# ATmega324PB device description
Architecture: AVR8; Family: megaAVR
Registers are 8-bit, access not given, no defined reset value unless marked. A register's access mark holds for its fields unless they carry their own. Offsets are from the block's base; [hi:lo] are bit positions.

## LOCKBIT — Lockbits
Instances: LOCKBIT 0 in lockbits
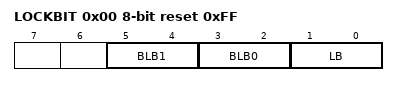
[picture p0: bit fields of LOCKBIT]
0x00 LOCKBIT reset 0xFF
  [5:4] BLB1 — Boot Loader Protection Mode
    0=LPM_SPM_DISABLE (LPM and SPM prohibited in Boot Section); 1=LPM_DISABLE (LPM prohibited in Boot Section); 2=SPM_DISABLE (SPM prohibited in Boot Section); 3=NO_LOCK (No lock on SPM and LPM in Boot Section)
  [3:2] BLB0 — Boot Loader Protection Mode
    0=LPM_SPM_DISABLE (LPM and SPM prohibited in Application Section); 1=LPM_DISABLE (LPM prohibited in Application Section); 2=SPM_DISABLE (SPM prohibited in Application Section); 3=NO_LOCK (No lock on SPM and LPM in Application Section)
  [1:0] LB — Memory Lock
    0=PROG_VER_DISABLED (Further programming and verification disabled); 2=PROG_DISABLED (Further programming disabled); 3=NO_LOCK (No memory lock features enabled)

## AC — Analog Comparator
Instances: AC 0x00
0x4F ACSRB — Analog Comparator Control And Status Register B
  [0] ACOE — Analog Comparator Output enable
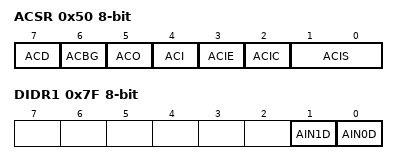
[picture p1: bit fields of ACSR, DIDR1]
0x50 ACSR — Analog Comparator Control And Status Register
  [7] ACD — Analog Comparator Disable
  [6] ACBG — Analog Comparator Bandgap Select
  [5] ACO — Analog Compare Output
  [4] ACI — Analog Comparator Interrupt Flag
  [3] ACIE — Analog Comparator Interrupt Enable
  [2] ACIC — Analog Comparator Input Capture Enable
  [1:0] ACIS — Analog Comparator Interrupt Mode Select bits
    0=Interrupt on Toggle; 2=Interrupt on Falling Edge; 3=Interrupt on Rising Edge
0x7F DIDR1 — Digital Input Disable Register 1
  [1] AIN1D — AIN1 Digital Input Disable
  [0] AIN0D — AIN0 Digital Input Disable

## USART0 — USART
Instances: USART0 0x00
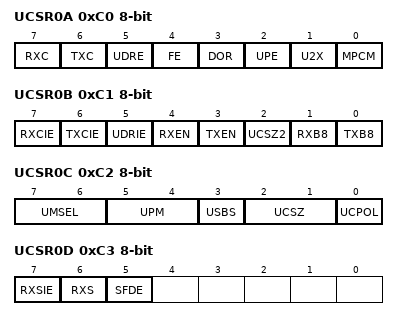
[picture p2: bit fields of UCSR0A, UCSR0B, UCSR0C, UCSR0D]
0xC0 UCSR0A — USART Control and Status Register A
  [7] RXC — USART Receive Complete
  [6] TXC — USART Transmitt Complete
  [5] UDRE — USART Data Register Empty
  [4] FE — Framing Error
  [3] DOR — Data overRun
  [2] UPE — Parity Error
  [1] U2X — Double the USART transmission speed
  [0] MPCM — Multi-processor Communication Mode
0xC1 UCSR0B — USART Control and Status Register B
  [7] RXCIE — RX Complete Interrupt Enable
  [6] TXCIE — TX Complete Interrupt Enable
  [5] UDRIE — USART Data register Empty Interrupt Enable
  [4] RXEN — Receiver Enable
  [3] TXEN — Transmitter Enable
  [2] UCSZ2 — Character Size
  [1] RXB8 — Receive Data Bit 8
  [0] TXB8 — Transmit Data Bit 8
0xC2 UCSR0C — USART Control and Status Register C
  [7:6] UMSEL — USART Mode Select
    0=Asynchronous Operation; 1=Synchronous Operation; 3=Master SPI
  [5:4] UPM — Parity Mode Bits
    0=Disabled; 2=Enabled, Even Parity; 3=Enabled, Odd Parity
  [3] USBS — Stop Bit Select
    0=1-bit; 1=2-bit
  [2:1] UCSZ — Character Size
  [0] UCPOL — Clock Polarity
0xC3 UCSR0D — USART Control and Status Register D
  [7] RXSIE — RX Start Frame Interrupt Enable
  [6] RXS — Start Frame Detect Flag
  [5] SFDE — Start Frame Detection Enable
0xC4 UBRR0 16-bit bits used 11:0 — USART Baud Rate Register Bytes
0xC6 UDR0 — USART I/O Data Register

## USART1 — USART
Instances: USART1 0x00
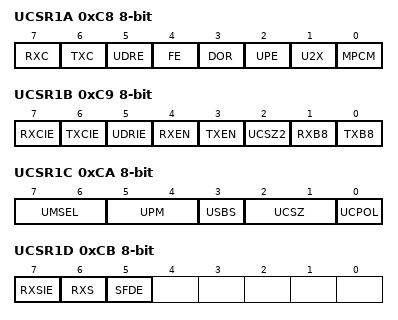
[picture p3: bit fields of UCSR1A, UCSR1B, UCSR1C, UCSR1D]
0xC8 UCSR1A — USART Control and Status Register A
  [7] RXC — USART Receive Complete
  [6] TXC — USART Transmitt Complete
  [5] UDRE — USART Data Register Empty
  [4] FE — Framing Error
  [3] DOR — Data overRun
  [2] UPE — Parity Error
  [1] U2X — Double the USART transmission speed
  [0] MPCM — Multi-processor Communication Mode
0xC9 UCSR1B — USART Control and Status Register B
  [7] RXCIE — RX Complete Interrupt Enable
  [6] TXCIE — TX Complete Interrupt Enable
  [5] UDRIE — USART Data register Empty Interrupt Enable
  [4] RXEN — Receiver Enable
  [3] TXEN — Transmitter Enable
  [2] UCSZ2 — Character Size
  [1] RXB8 — Receive Data Bit 8
  [0] TXB8 — Transmit Data Bit 8
0xCA UCSR1C — USART Control and Status Register C
  [7:6] UMSEL — USART Mode Select
    0=Asynchronous Operation; 1=Synchronous Operation; 3=Master SPI
  [5:4] UPM — Parity Mode Bits
    0=Disabled; 2=Enabled, Even Parity; 3=Enabled, Odd Parity
  [3] USBS — Stop Bit Select
    0=1-bit; 1=2-bit
  [2:1] UCSZ — Character Size
  [0] UCPOL — Clock Polarity
0xCB UCSR1D — USART Control and Status Register D
  [7] RXSIE — RX Start Frame Interrupt Enable
  [6] RXS — Start Frame Detect Flag
  [5] SFDE — Start Frame Detection Enable
0xCC UBRR1 16-bit bits used 11:0 — USART Baud Rate Register Bytes
0xCE UDR1 — USART I/O Data Register
